# dm64lc_cslr_hecc_ram register map
Vendor: Texas Instruments
Peripheral module from a debugger description file.
Registers are 32-bit, read-write, reset 0x0 unless marked. A register's access mark holds for its fields unless they carry their own. Offsets are as the file gives them; lines under a group give offsets from that group; [hi:lo] are bit positions; {n}, {i} and the like mark numbered series; 'fields as' and 'values as' point back to an identical list; <NAME> marks a mode.

## HECCRAM — This module provides an interface to program the High End CAN Controller (HECC) RAM.
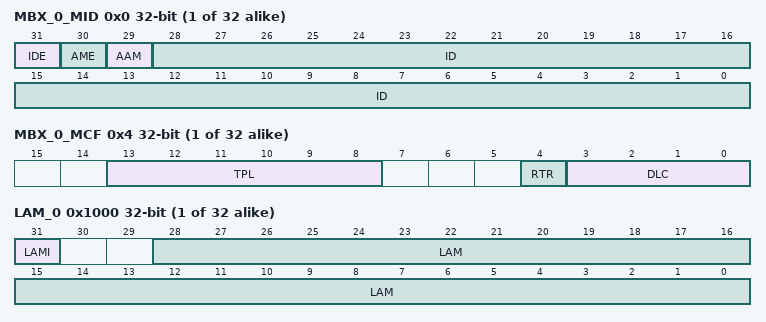
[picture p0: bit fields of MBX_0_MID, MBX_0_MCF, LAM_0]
{0x0+8i} MBX_{i}_MID (i=0..31) — Message Identifier Registers
  [31] IDE — Identifier Extension bit
  [30] AME — Acceptance Mask Enable
  [29] AAM — Auto Answer Mode
  [28:0] ID — Message Identifier
{0x4+8i} MBX_{i}_MCF access not given (i=0..31) — Message Control Registers
  [13:8] TPL rw — Transmit Priority Level
  [4] RTR rw — Remote Transmission Request
  [3:0] DLC rw — Data Length Code
{0x8+8i} MBX_{i}_MDL (i=0..31) — Message Data Low Register
  [31:0] MDL — Lower 32-bit Data
{0xC+8i} MBX_{i}_MDH (i=0..31) — Message Data High Register
  [31:0] MDH — Upper 32-bit Data
{0x1000+4i} LAM_{i} access not given (i=0..31) — Local Acceptance Mask Register
  [31] LAMI rw — Local Acceptance Mask Identifier
  [28:0] LAM rw — Local Acceptance Mask
{0x1080+4i} MOTS_{i} (i=0..31) — Message Object Time Stamp Registers
  [31:0] MOTS — 32-bit Message Object Time Stamp
{0x1110+4i} MOTO_{i} (i=0..31) — Message Object Time-Out Registers
  [31:0] MOTO — 32-bit Message Object Time-Out
